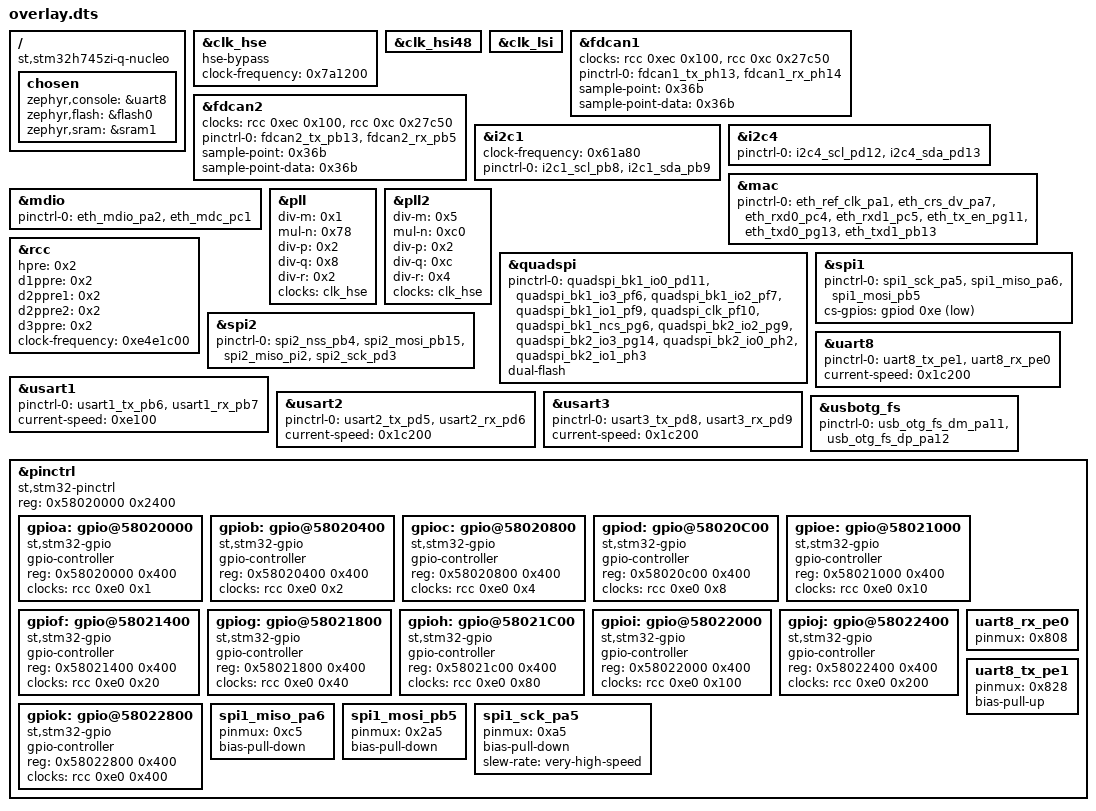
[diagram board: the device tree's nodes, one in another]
/ {
	compatible = "st,stm32h745zi-q-nucleo";
	chosen {
		zephyr,console = &uart8;
		zephyr,flash = &flash0;
		zephyr,sram = &sram1;
	};
};
&clk_hse{
	status = "okay";
	hse-bypass;
	clock-frequency = < 0x7a1200 >;
};
&clk_hsi48{
	status = "okay";
};
&clk_lsi{
	status = "okay";
};
&fdcan1{
	clocks = < &rcc 0xec 0x100 >, < &rcc 0xc 0x27c50 >;
	status = "okay";
	pinctrl-0 = < &fdcan1_tx_ph13 &fdcan1_rx_ph14 >;
	pinctrl-names = "default";
	sample-point = < 0x36b >;
	sample-point-data = < 0x36b >;
};
&fdcan2{
	clocks = < &rcc 0xec 0x100 >, < &rcc 0xc 0x27c50 >;
	status = "okay";
	pinctrl-0 = < &fdcan2_tx_pb13 &fdcan2_rx_pb5 >;
	pinctrl-names = "default";
	sample-point = < 0x36b >;
	sample-point-data = < 0x36b >;
};
&i2c1{
	clock-frequency = < 0x61a80 >;
	status = "okay";
	pinctrl-0 = < &i2c1_scl_pb8 &i2c1_sda_pb9 >;
	pinctrl-names = "default";
};
&i2c4{
	status = "okay";
	pinctrl-0 = < &i2c4_scl_pd12 &i2c4_sda_pd13 >;
	pinctrl-names = "default";
};
&mac{
	status = "okay";
	pinctrl-0 = < &eth_ref_clk_pa1 &eth_crs_dv_pa7 &eth_rxd0_pc4 &eth_rxd1_pc5 &eth_tx_en_pg11 &eth_txd0_pg13 &eth_txd1_pb13 >;
	pinctrl-names = "default";
};
&mdio{
	status = "okay";
	pinctrl-0 = < &eth_mdio_pa2 &eth_mdc_pc1 >;
	pinctrl-names = "default";
};
&pll{
	status = "okay";
	div-m = < 0x1 >;
	mul-n = < 0x78 >;
	div-p = < 0x2 >;
	div-q = < 0x8 >;
	div-r = < 0x2 >;
	clocks = < &clk_hse >;
};
&pll2{
	status = "okay";
	div-m = < 0x5 >;
	mul-n = < 0xc0 >;
	div-p = < 0x2 >;
	div-q = < 0xc >;
	div-r = < 0x4 >;
	clocks = < &clk_hse >;
};
&quadspi{
	status = "okay";
	pinctrl-names = "default";
	pinctrl-0 = < &quadspi_bk1_io0_pd11 &quadspi_bk1_io3_pf6 &quadspi_bk1_io2_pf7 &quadspi_bk1_io1_pf9 &quadspi_clk_pf10 &quadspi_bk1_ncs_pg6 &quadspi_bk2_io2_pg9 &quadspi_bk2_io3_pg14 &quadspi_bk2_io0_ph2 &quadspi_bk2_io1_ph3 >;
	dual-flash;
};
&rcc{
	hpre = < 0x2 >;
	d1ppre = < 0x2 >;
	d2ppre1 = < 0x2 >;
	d2ppre2 = < 0x2 >;
	d3ppre = < 0x2 >;
	clock-frequency = < 0xe4e1c00 >;
};
&spi1{
	status = "okay";
	pinctrl-0 = < &spi1_sck_pa5 &spi1_miso_pa6 &spi1_mosi_pb5 >;
	pinctrl-names = "default";
	cs-gpios = < &gpiod 0xe 0x11 >;
};
&spi2{
	status = "okay";
	pinctrl-0 = < &spi2_nss_pb4 &spi2_mosi_pb15 &spi2_miso_pi2 &spi2_sck_pd3 >;
	pinctrl-names = "default";
};
&uart8{
	status = "okay";
	pinctrl-0 = < &uart8_tx_pe1 &uart8_rx_pe0 >;
	pinctrl-names = "default";
	current-speed = < 0x1c200 >;
};
&usart1{
	status = "okay";
	pinctrl-0 = < &usart1_tx_pb6 &usart1_rx_pb7 >;
	pinctrl-names = "default";
	current-speed = < 0xe100 >;
};
&usart2{
	status = "okay";
	pinctrl-0 = < &usart2_tx_pd5 &usart2_rx_pd6 >;
	pinctrl-names = "default";
	current-speed = < 0x1c200 >;
};
&usart3{
	status = "okay";
	pinctrl-0 = < &usart3_tx_pd8 &usart3_rx_pd9 >;
	pinctrl-names = "default";
	current-speed = < 0x1c200 >;
};
&usbotg_fs{
	status = "okay";
	pinctrl-0 = < &usb_otg_fs_dm_pa11 &usb_otg_fs_dp_pa12 >;
	pinctrl-names = "default";
};
&pinctrl{
	compatible = "st,stm32-pinctrl";
	#address-cells = < 0x1 >;
	#size-cells = < 0x1 >;
	reg = < 0x58020000 0x2400 >;
	gpioa: gpio@58020000 {
		compatible = "st,stm32-gpio";
		gpio-controller;
		#gpio-cells = < 0x2 >;
		reg = < 0x58020000 0x400 >;
		clocks = < &rcc 0xe0 0x1 >;
	};
	gpiob: gpio@58020400 {
		compatible = "st,stm32-gpio";
		gpio-controller;
		#gpio-cells = < 0x2 >;
		reg = < 0x58020400 0x400 >;
		clocks = < &rcc 0xe0 0x2 >;
	};
	gpioc: gpio@58020800 {
		compatible = "st,stm32-gpio";
		gpio-controller;
		#gpio-cells = < 0x2 >;
		reg = < 0x58020800 0x400 >;
		clocks = < &rcc 0xe0 0x4 >;
	};
	gpiod: gpio@58020C00 {
		compatible = "st,stm32-gpio";
		gpio-controller;
		#gpio-cells = < 0x2 >;
		reg = < 0x58020c00 0x400 >;
		clocks = < &rcc 0xe0 0x8 >;
	};
	gpioe: gpio@58021000 {
		compatible = "st,stm32-gpio";
		gpio-controller;
		#gpio-cells = < 0x2 >;
		reg = < 0x58021000 0x400 >;
		clocks = < &rcc 0xe0 0x10 >;
	};
	gpiof: gpio@58021400 {
		compatible = "st,stm32-gpio";
		gpio-controller;
		#gpio-cells = < 0x2 >;
		reg = < 0x58021400 0x400 >;
		clocks = < &rcc 0xe0 0x20 >;
	};
	gpiog: gpio@58021800 {
		compatible = "st,stm32-gpio";
		gpio-controller;
		#gpio-cells = < 0x2 >;
		reg = < 0x58021800 0x400 >;
		clocks = < &rcc 0xe0 0x40 >;
	};
	gpioh: gpio@58021C00 {
		compatible = "st,stm32-gpio";
		gpio-controller;
		#gpio-cells = < 0x2 >;
		reg = < 0x58021c00 0x400 >;
		clocks = < &rcc 0xe0 0x80 >;
	};
	gpioi: gpio@58022000 {
		compatible = "st,stm32-gpio";
		gpio-controller;
		#gpio-cells = < 0x2 >;
		reg = < 0x58022000 0x400 >;
		clocks = < &rcc 0xe0 0x100 >;
	};
	gpioj: gpio@58022400 {
		compatible = "st,stm32-gpio";
		gpio-controller;
		#gpio-cells = < 0x2 >;
		reg = < 0x58022400 0x400 >;
		clocks = < &rcc 0xe0 0x200 >;
	};
	gpiok: gpio@58022800 {
		compatible = "st,stm32-gpio";
		gpio-controller;
		#gpio-cells = < 0x2 >;
		reg = < 0x58022800 0x400 >;
		clocks = < &rcc 0xe0 0x400 >;
	};
	spi1_miso_pa6: spi1_miso_pa6 {
		pinmux = < 0xc5 >;
		bias-pull-down;
	};
	spi1_mosi_pb5: spi1_mosi_pb5 {
		pinmux = < 0x2a5 >;
		bias-pull-down;
	};
	spi1_sck_pa5: spi1_sck_pa5 {
		pinmux = < 0xa5 >;
		bias-pull-down;
		slew-rate = "very-high-speed";
	};
	uart8_rx_pe0: uart8_rx_pe0 {
		pinmux = < 0x808 >;
	};
	uart8_tx_pe1: uart8_tx_pe1 {
		pinmux = < 0x828 >;
		bias-pull-up;
	};
};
